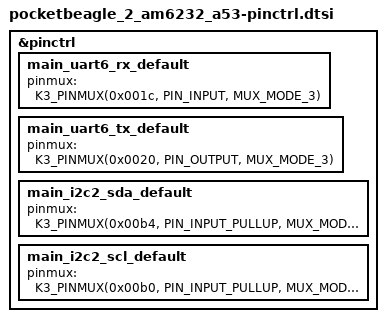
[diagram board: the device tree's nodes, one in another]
/*
 * Copyright (c) 2025 Ayush Singh, BeagleBoard.org Foundation
 *
 * SPDX-License-Identifier: Apache-2.0
 */

#include <zephyr/dt-bindings/pinctrl/ti-k3-pinctrl.h>

&pinctrl {
	main_uart6_rx_default: main_uart6_rx_default {
		pinmux = <K3_PINMUX(0x001c, PIN_INPUT, MUX_MODE_3)>;
	};

	main_uart6_tx_default: main_uart6_tx_default {
		pinmux = <K3_PINMUX(0x0020, PIN_OUTPUT, MUX_MODE_3)>;
	};

	main_i2c2_sda_default: main_i2c2_sda_default {
		/* (K24) GPMC0_CSn3.I2C2_SDA */
		pinmux = <K3_PINMUX(0x00b4, PIN_INPUT_PULLUP, MUX_MODE_1)>;
	};

	main_i2c2_scl_default: main_i2c2_scl_default {
		/* (K22) GPMC0_CSn2.I2C2_SCL */
		pinmux = <K3_PINMUX(0x00b0, PIN_INPUT_PULLUP, MUX_MODE_1)>;
	};
};
